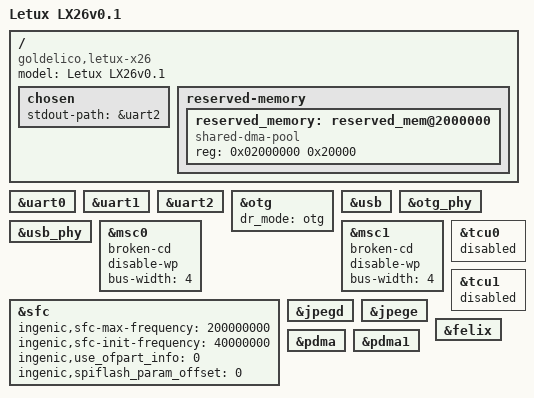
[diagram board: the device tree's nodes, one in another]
/dts-v1/;

#include <dt-bindings/gpio/gpio.h>
#include <dt-bindings/input/input.h>
#include <dt-bindings/interrupt-controller/irq.h>
#include "x2600.dtsi"

// Mapping of RasPi functions to 40 pin RasPi connector (you can either use pin or signal names)
#define SDA	PIN3
#define SCL	PIN5
#define IO4	PIN7
#define TXD	PIN8
#define RXD	PIN10
#define IO17	PIN11
#define PCM_CLK	PIN12
#define IO18	PIN12
#define IO27	PIN13
#define IO22	PIN15
#define IO23	PIN16
#define IO24	PIN18
#define MOSI	PIN19
#define IO10	PIN19
#define MISO	PIN21
#define IO9	PIN21
#define IO25	PIN22
#define SCLK	PIN23
#define IO11	PIN23
#define CE0	PIN24
#define IO8	PIN24
#define CE1	PIN26
#define IO7	PIN26
#define IDSD	PIN27
#define IDSC	PIN28
#define IO5	PIN29
#define IO6	PIN31
#define IO12	PIN32
#define IO13	PIN33
#define IO19	PIN35
#define IO16	PIN36
#define IO26	PIN37
#define IO20	PIN38
#define IO21	PIN40

// Mapping of connector pins to LX26 signals
#define PIN3	PC3_SDA
#define PIN5	PC2_SCL
#define PIN7	PB4
#define PIN8	PC12
#define PIN10	PC11
#define PIN11	PB17
#define PIN12	PB18
#define PIN13	PB27
#define PIN15	PB22
#define PIN16	PB23
#define PIN18	PB24
#define PIN19	PB2_MOSI
#define PIN21	PB1_MISO
#define PIN22	PB25
#define PIN23	PB3_SCLK
#define PIN24	PB0_CE
#define PIN26	PB7
#define PIN27	PC1_SDA
#define PIN28	PC0_SCL
#define PIN29	PB5
#define PIN31	PB6
#define PIN32	PB12
#define PIN33	PB13
#define PIN35	PB19
#define PIN36	PB16
#define PIN37	PB26
#define PIN38	PB20
#define PIN40	PB21

// Mapping of LX26 signals to x2600 gpios/pins
#define PB0_CE		&gpb 0
#define PB1_MISO	&gpb 1
#define PB2_MOSI	&gpb 2
#define PB3_SCLK	&gpb 3
#define PB4		&gpb 4
#define PB5		&gpb 5
#define PB6		&gpb 6
#define PB7		&gpb 7
#define PB12		&gpb 12
#define PB13		&gpb 13
#define PB17		&gpb 17
#define PB18		&gpb 18
#define PB19		&gpb 19
#define PB20		&gpb 20
#define PB21		&gpb 21
#define PB22		&gpb 22
#define PB23		&gpb 23
#define PB24		&gpb 24
#define PB25		&gpb 25
#define PB26		&gpb 26
#define PB27		&gpb 27
#define PC0_SCL		&gpc 0
#define PC1_SDA		&gpc 1
#define PC2_SCL		&gpc 2
#define PC3_SDA		&gpc 3
#define PC11		&gpc 11
#define PC12		&gpc 12

/ {
	compatible = "goldelico,letux-x26", "ingenic,x2600";

	model = "Letux LX26v0.1";

	chosen {
		stdout-path = &uart2;
#if 0	// u-boot and optionally CONFIG_CMDLINE should provide something application specific
		bootargs = "mem=128M@0x0 ieee754=emulated rootfstype=ext4 root=/dev/mmcblk0p2 rw earlycon console=ttyS2,115200 clk_ignore_unused ignore_loglevel rootwait";
#endif
	};

	reserved-memory {
		#address-cells = <1>;
		#size-cells = <1>;
		ranges =<>;

		reserved_memory: reserved_mem@2000000{
		      compatible = "shared-dma-pool";
		      reg = <0x02000000 0x20000>;
		};
	};

};

&uart0 {
	status = "okay";
#if 0	// FIXME
	pinctrl-names = "default";
	pinctrl-0 = <&uart0_pe>;
#endif
};

&uart1 {
	status = "okay";
#if 0	// FIXME
	pinctrl-names = "default";
	pinctrl-0 = <&uart1_pb>;
#endif
};

&uart2 {
	status = "okay";
#if 0	// FIXME
	pinctrl-names = "default";
	pinctrl-0 = <&uart2_pd>;
#endif
};

&otg {
	dr_mode = "otg"; // host,peripheral,otg
	status = "okay";
};

&usb {
	status = "okay";
};

&otg_phy {
	status = "okay";
};

&usb_phy {
	status = "okay";
};

&msc0 {
	status = "okay";
	broken-cd;	// there is a GPIO for CD
	disable-wp;
	bus-width = <4>;
};

&msc1 {
	status = "okay";
	broken-cd;	// there is a GPIO for CD
	disable-wp;
	bus-width = <4>;
};

#if 0	// needs a new mechanism to control this
&pinctrl {
	ingenic,gpa_voltage = <GPIO_VOLTAGE_1V8>;
	ingenic,gpe_msc_voltage = <GPIO_VOLTAGE_1V8>;
};
#endif

&sfc {
	status = "okay";
#if 0 // FIXME
	pinctrl-names = "default";
	pinctrl-0 = <&sfc_pd1>;
#endif
	ingenic,sfc-max-frequency = <200000000>;
	ingenic,sfc-init-frequency= <40000000>;
	ingenic,use_ofpart_info  = /bits/ 8 <0>;
	ingenic,spiflash_param_offset = <0>;
};

&tcu0 {
	status = "disable";
};

&tcu1 {
	status = "disable";
};

&jpegd {
    status = "okay";
};

&jpege {
    status = "okay";
};

&felix {
	status = "okay";
};

&pdma {
	status = "okay";
};

&pdma1 {
	status = "okay";
};
